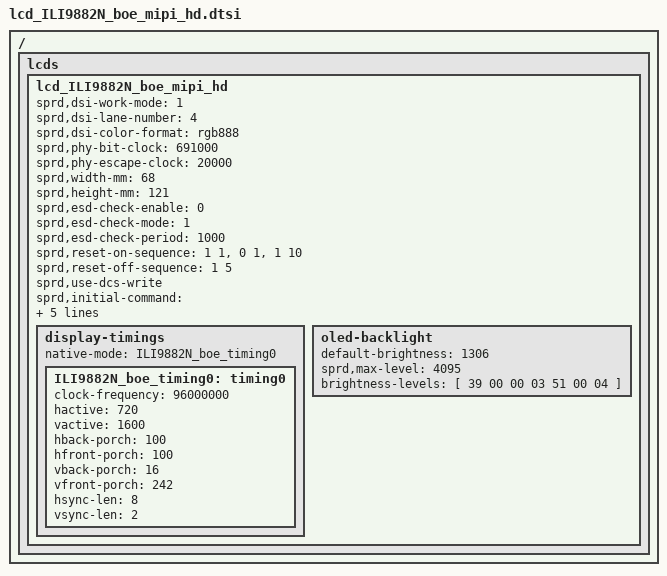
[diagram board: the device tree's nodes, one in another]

/*
 * R61350 Truly LCD config dtsi file for spreadtrum
 *
 * Copyright (C) 2018, Spreadtrum Communications Inc.
 *
 * SPDX-License-Identifier: (GPL-2.0+ OR MIT)
 */

/ {
	fragment {
		target-path = "/";
		__overlay__ {
			lcds {
				lcd_ILI9882N_boe_mipi_hd: lcd_ILI9882N_boe_mipi_hd {

					sprd,dsi-work-mode = <1>; /* video burst mode*/
					sprd,dsi-lane-number = <4>;
					sprd,dsi-color-format = "rgb888";

					sprd,phy-bit-clock = <691000>;	/* kbps */
					sprd,phy-escape-clock = <20000>;/* kHz */

					sprd,width-mm = <68>;
					sprd,height-mm = <121>;

					sprd,esd-check-enable = <0>;
					sprd,esd-check-mode = <1>;
					sprd,esd-check-period = <1000>;
					/* sprd,esd-check-register = <0x0A>; */
					/* sprd,esd-check-value = <0x9C>; */

					sprd,reset-on-sequence = <1 1>, <0 1>, <1 10>;
					sprd,reset-off-sequence = <1 5>;

 
					sprd,use-dcs-write;
					sprd,initial-command = [
								39 00 00 04 FF 98 82 01 
								39 00 00 02 00 44 
								39 00 00 02 01 13 
								39 00 00 02 02 10 
								39 00 00 02 03 20 
								39 00 00 02 04 CA 
								39 00 00 02 05 13 
								39 00 00 02 06 10 
								39 00 00 02 07 20 
								39 00 00 02 08 82 
								39 00 00 02 09 09 
								39 00 00 02 0a b3 
								39 00 00 02 0b 00 
								39 00 00 02 0c 17 
								39 00 00 02 0d 17 
								39 00 00 02 0e 04 
								39 00 00 02 0f 04 
								39 00 00 02 10 0A 
								39 00 00 02 11 0A 
								39 00 00 02 12 09 
								39 00 00 02 1E 0A 
								39 00 00 02 1F 0A 
								39 00 00 02 16 82 
								39 00 00 02 17 09 
								39 00 00 02 18 33 
								39 00 00 02 19 00 
								39 00 00 02 1a 17 
								39 00 00 02 1b 17 
								39 00 00 02 1c 04 
								39 00 00 02 1d 04 
								39 00 00 02 20 09 
								39 00 00 02 24 02 
								39 00 00 02 25 0b 
								39 00 00 02 26 10 
								39 00 00 02 27 20 
								39 00 00 02 2c 34 
								39 00 00 02 31 07 
								39 00 00 02 32 2a 
								39 00 00 02 33 2a 
								39 00 00 02 34 0D 
								39 00 00 02 35 28 
								39 00 00 02 36 29 
								39 00 00 02 37 11 
								39 00 00 02 38 13 
								39 00 00 02 39 15 
								39 00 00 02 3a 17 
								39 00 00 02 3b 19 
								39 00 00 02 3c 1b 
								39 00 00 02 3d 09 
								39 00 00 02 3e 07 
								39 00 00 02 3f 07 
								39 00 00 02 40 07 
								39 00 00 02 41 07 
								39 00 00 02 42 07 
								39 00 00 02 43 07 
								39 00 00 02 44 07 
								39 00 00 02 45 07 
								39 00 00 02 46 07 
								39 00 00 02 47 07 
								39 00 00 02 48 2a 
								39 00 00 02 49 2a 
								39 00 00 02 4a 0C 
								39 00 00 02 4b 28 
								39 00 00 02 4c 29 
								39 00 00 02 4d 10 
								39 00 00 02 4e 12 
								39 00 00 02 4f 14 
								39 00 00 02 50 16 
								39 00 00 02 51 18 
								39 00 00 02 52 1a 
								39 00 00 02 53 08 
								39 00 00 02 54 07 
								39 00 00 02 55 07 
								39 00 00 02 56 07 
								39 00 00 02 57 07 
								39 00 00 02 58 07 
								39 00 00 02 59 07 
								39 00 00 02 5a 07 
								39 00 00 02 5b 07 
								39 00 00 02 5c 07 
								39 00 00 02 61 07 
								39 00 00 02 62 2a 
								39 00 00 02 63 2a 
								39 00 00 02 64 0D 
								39 00 00 02 65 28 
								39 00 00 02 66 29 
								39 00 00 02 67 11 
								39 00 00 02 68 13 
								39 00 00 02 69 15 
								39 00 00 02 6a 17 
								39 00 00 02 6b 19 
								39 00 00 02 6c 1b 
								39 00 00 02 6d 09 
								39 00 00 02 6e 07 
								39 00 00 02 6f 07 
								39 00 00 02 70 07 
								39 00 00 02 71 07 
								39 00 00 02 72 07 
								39 00 00 02 73 07 
								39 00 00 02 74 07 
								39 00 00 02 75 07 
								39 00 00 02 76 07 
								39 00 00 02 77 07 
								39 00 00 02 78 2a 
								39 00 00 02 79 2a 
								39 00 00 02 7a 0C 
								39 00 00 02 7b 28 
								39 00 00 02 7c 29 
								39 00 00 02 7d 10 
								39 00 00 02 7e 12 
								39 00 00 02 7f 14 
								39 00 00 02 80 16 
								39 00 00 02 81 18 
								39 00 00 02 82 1a 
								39 00 00 02 83 08 
								39 00 00 02 84 07 
								39 00 00 02 85 07 
								39 00 00 02 86 07 
								39 00 00 02 87 07 
								39 00 00 02 88 07 
								39 00 00 02 89 07 
								39 00 00 02 8a 07 
								39 00 00 02 8b 07 
								39 00 00 02 8c 07 
								39 00 00 02 A0 01 
								39 00 00 02 A2 00 
								39 00 00 02 A3 00 
								39 00 00 02 A4 00 
								39 00 00 02 A5 00 
								39 00 00 02 A6 00 
								39 00 00 02 A7 00  // modify for sensor mura by shawn_20200515
								39 00 00 02 A8 00  // modify for sensor mura by shawn_20200515
								39 00 00 02 A9 04 
								39 00 00 02 AA 04 
								39 00 00 02 AB 00  // modify for sensor mura by shawn_20200515
								39 00 00 02 AC 00  // modify for sensor mura by shawn_20200515
								39 00 00 02 AD 04 
								39 00 00 02 AE 04 
								39 00 00 02 B0 33 
								39 00 00 02 B1 33 
								39 00 00 02 B2 00 
								39 00 00 02 B9 40 
								39 00 00 02 C3 FF 
								39 00 00 02 CA 44 
								39 00 00 02 D0 01 
								39 00 00 02 D1 00 
								39 00 00 02 DC 37 
								39 00 00 02 DD 42 
								39 00 00 02 E2 00 
								39 00 00 02 E6 23 
								39 00 00 02 E7 54 
								39 00 00 02 ED 00 

								// RTN. Internal VBP, 0x Internal VFP  IC TIMMING
								39 00 00 04 FF 98 82 02 
								39 00 00 02 F1 1C 
								39 00 00 02 4B 5A 
								39 00 00 02 50 CA 
								39 00 00 02 51 00 
								39 00 00 02 06 8E 
								39 00 00 02 0B A0 
								39 00 00 02 0C 00 
								39 00 00 02 0D 12 
								39 00 00 02 0E F2 
								39 00 00 02 4E 11 

								39 00 00 04 FF 98 82 03    // CABC  START V1 PARA  2020-9-25
								39 00 00 02 88 d3 
								39 00 00 02 89 e9 
								39 00 00 02 8A ec 
								39 00 00 02 8B ef 
								39 00 00 02 B3 eb 
								39 00 00 02 ac fa 

								39 00 00 02 ad e4 
								39 00 00 02 8C a5 
								39 00 00 02 8D a9 
								39 00 00 02 8E ad 
								39 00 00 02 8F b3 
								39 00 00 02 90 bb 
								39 00 00 02 91 bc 
								39 00 00 02 92 bd 
								39 00 00 02 93 bf 
								39 00 00 02 94 c1 
								39 00 00 02 95 d5 
								39 00 00 02 B4 bf 

								39 00 00 02 ae da 
								39 00 00 02 96 7a 
								39 00 00 02 97 89 
								39 00 00 02 98 99 
								39 00 00 02 99 a5 
								39 00 00 02 9A ae 
								39 00 00 02 9B af 
								39 00 00 02 9C b0 
								39 00 00 02 9D b3 
								39 00 00 02 9E b7 
								39 00 00 02 9F cc 
								39 00 00 02 B5 b0             // CABC  END V1 PARA  2020-9-25
								// Power Setting
								39 00 00 04 FF 98 82 05 
								39 00 00 02 03 01 
								39 00 00 02 04 13 
								39 00 00 02 63 9C 
								39 00 00 02 64 9C 
								39 00 00 02 46 00 
								39 00 00 02 47 0A 
								39 00 00 02 85 77 
								39 00 00 02 68 8D 
								39 00 00 02 69 93 
								39 00 00 02 6A C9 
								39 00 00 02 6B BB 
								39 00 00 02 C8 8D 
								39 00 00 02 C9 8D 
								39 00 00 02 CA 8D 
								39 00 00 02 CB 8D 
								39 00 00 02 D0 93 
								39 00 00 02 D1 93 
								39 00 00 02 D2 93 
								39 00 00 02 D3 93 

								// Resolution
								39 00 00 04 FF 98 82 06 
								39 00 00 02 D9 1f 
								39 00 00 02 C0 40 
								39 00 00 02 C1 16 
								39 00 00 02 06 A4 

								39 00 00 04 FF 98 82 07 
								39 00 00 02 C0 01 
								39 00 00 02 CB CF 
								39 00 00 02 CC B0 
								39 00 00 02 CD 9D 
								39 00 00 02 CE 7E 

								// Gamma Register
								39 00 00 04 FF 98 82 08 
								39 00 00 1C E0 00 24 4C 70 9F 50 CA ED 18 3D 95 77 A9 D6 01 AA 2E 65 89 B6 FE DD 11 52 88 03 EC 
								39 00 00 1C E1 00 24 4C 70 9F 50 CA ED 18 3D 95 77 A9 D6 01 AA 2E 65 89 B6 FE DD 11 52 88 03 EC 

								39 00 00 04 FF 98 82 0a 
								39 00 00 AF 00 00 02 04 07 0B 0F 13 17 1B 1E 22 26 2A 2D 31 35 39 3D 41 45 48 4C 4F 53 5B 62 6A 79 88 90 98 9F A6 AE B5 BD C4 CC D3 DA E2 EA EB ED EF F0 C8 77 B8 6C 15 92 8C 46 2B E7 F2 0A 00 02 04 07 0C 10 14 18 1C 1F 23 27 2B 2F 33 36 3B 3F 43 46 4A 4E 51 55 5D 65 6D 7C 8C 94 9C A4 AC B4 BB C3 CB D3 DB E3 EB F3 F5 F7 F9 FA C4 10 F8 C4 C4 F2 DB 7E A1 4A 55 09 01 01 04 09 0D 11 15 18 1C 20 24 28 2C 30 34 38 3D 41 45 49 4D 51 55 59 61 69 71 81 91 99 A1 A9 B1 B8 C0 C9 D0 D8 E0 E8 F0 F7 FA FC FD FF 19 45 B5 FE 69 50 6A 5E 3D A6 0D 03 
								39 00 00 02 80 01 
								// OSC Auto Trim Setting  IC  TIMMING
								39 00 00 04 FF 98 82 0B 
								39 00 00 02 9A 44 
								39 00 00 02 9B 7A 
								39 00 00 02 9C 03 
								39 00 00 02 9D 03 
								39 00 00 02 9E 70 
								39 00 00 02 9F 70 
								39 00 00 02 AB E0 

								39 00 00 04 FF 98 82 0E 
								39 00 00 02 11 10 
								39 00 00 02 13 10 
								39 00 00 02 00 A0 
								39 00 00 04 FF 98 82 03 
								39 00 00 02 83 20 
								39 00 00 02 84 00 	//PWM

								39 00 00 04 FF 98 82 00 
								39 00 00 02 53 24 
								39 00 00 02 55 01 
								39 00 00 02 35 00 
								39 78 00 02 11 00 
								39 00 00 03 51 0F FF 
								39 00 00 02 53 24 
								39 0A 00 02 55 00
								39 32 00 02 29 00 
					
						];

                                       

					sprd,sleep-in-command = [
						15 5A 00 01 28
						15 3C 00 01 10 
						
						];

					sprd,sleep-out-command = [
						15 78 00 01 11
						15 14 00 01 29
						];

					display-timings {
						native-mode = <&ILI9882N_boe_timing0>;

						ILI9882N_boe_timing0: timing0 {
							clock-frequency = <96000000>;
							hactive = <720>;
							vactive = <1600>;
							hback-porch = <100>;
							hfront-porch = <100>;
							vback-porch = <16>;
							vfront-porch = <242>;
							hsync-len = <8>;
							vsync-len = <2>;
						};
					};

					
					oled-backlight {			
						default-brightness = <1306>;	
						sprd,max-level = <4095>;
						brightness-levels = [				
							39 00 00 03 51 00 04	
						];
					};
				};
			};
		};
	};
};
